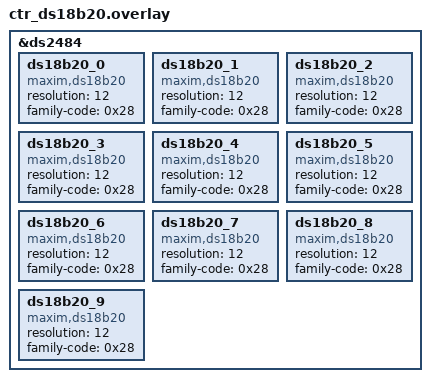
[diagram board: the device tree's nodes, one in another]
/*
 * Copyright (c) 2023 HARDWARIO a.s.
 *
 * SPDX-License-Identifier: LicenseRef-HARDWARIO-5-Clause
 */

&ds2484 {
	ds18b20_0: ds18b20_0 {
		compatible = "maxim,ds18b20";
		resolution = <12>;
		family-code = <0x28>;
	};

	ds18b20_1: ds18b20_1 {
		compatible = "maxim,ds18b20";
		resolution = <12>;
		family-code = <0x28>;
	};

	ds18b20_2: ds18b20_2 {
		compatible = "maxim,ds18b20";
		resolution = <12>;
		family-code = <0x28>;
	};

	ds18b20_3: ds18b20_3 {
		compatible = "maxim,ds18b20";
		resolution = <12>;
		family-code = <0x28>;
	};

	ds18b20_4: ds18b20_4 {
		compatible = "maxim,ds18b20";
		resolution = <12>;
		family-code = <0x28>;
	};

	ds18b20_5: ds18b20_5 {
		compatible = "maxim,ds18b20";
		resolution = <12>;
		family-code = <0x28>;
	};

	ds18b20_6: ds18b20_6 {
		compatible = "maxim,ds18b20";
		resolution = <12>;
		family-code = <0x28>;
	};

	ds18b20_7: ds18b20_7 {
		compatible = "maxim,ds18b20";
		resolution = <12>;
		family-code = <0x28>;
	};

	ds18b20_8: ds18b20_8 {
		compatible = "maxim,ds18b20";
		resolution = <12>;
		family-code = <0x28>;
	};

	ds18b20_9: ds18b20_9 {
		compatible = "maxim,ds18b20";
		resolution = <12>;
		family-code = <0x28>;
	};
};
